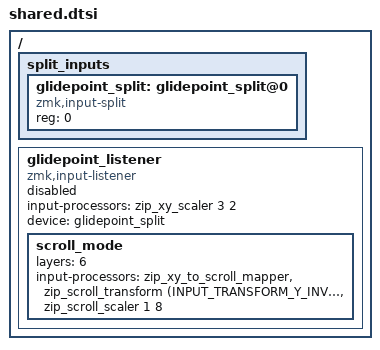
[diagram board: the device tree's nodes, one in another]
#include <input/processors.dtsi>
#include <dt-bindings/zmk/pointing.h>
#include <dt-bindings/zmk/input_transform.h>

/ {
    split_inputs {
        #address-cells = <1>;
        #size-cells = <0>;

        glidepoint_split: glidepoint_split@0 {
            compatible = "zmk,input-split";
            reg = <0>;
        };
    };

    glidepoint_listener: glidepoint_listener {
        compatible = "zmk,input-listener";
        input-processors = <&zip_xy_scaler 3 2>;
        status = "disabled";
        device = <&glidepoint_split>;
        
        // Scroll setup using layer override
        scroll_mode {
            layers = <6>;  // Use a layer for scrolling
            input-processors = <&zip_xy_to_scroll_mapper>, <&zip_scroll_transform (INPUT_TRANSFORM_Y_INVERT | INPUT_TRANSFORM_X_INVERT)>, <&zip_scroll_scaler 1 8>;
        };

        // // Fast movement mode (warp)
        // warp {
        //     layers = <5>;  // Use layer 5 for warp functionality (fast movement)
        //     input-processors = <&zip_xy_scaler 2 1>;
        // };
        //
        // // Precision mode for slower movement
        // precision {
        //     layers = <2>;
        //     input-processors = <&zip_xy_scaler 5 4>;
        // };
    };
    
    // // Mouse move behavior customization
    // mmv {
    //     acceleration-exponent = <1>;      // Default: 1
    //     time-to-max-speed-ms = <500>;     // Lower = faster ramp-up to max speed (default: 300)
    //     delay-ms = <0>;                   // Default: 0
    // };
    //
    // // Mouse scroll behavior customization
    // msc {
    //     acceleration-exponent = <2>;      // Default: 0
    //     time-to-max-speed-ms = <300>;     // Default: 300
    //     delay-ms = <0>;                   // Default: 0
    //
    // };
};
